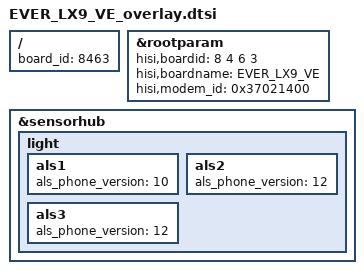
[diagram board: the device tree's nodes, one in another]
/**
 * Copyright (C) 2014 Hisilicon Ltd.
 *
 *  This program is free software; you can redistribute it and/or modify
 *  it under the terms of the GNU General Public License version 2 as
 *  publishhed by the Free Software Foundation.
 */


/include/ "EVER_LX9_VD_overlay.dtsi"

/ {
    board_id = <8463>;
};
	&rootparam{
		hisi,boardid = <8 4 6 3>;
		hisi,boardname = "EVER_LX9_VE";
		hisi,modem_id = <0x37021400>;
	};

	&sensorhub{
		light{
			als1{
				als_phone_version = <10>;
			};
			als2{
				als_phone_version = <12>;
			};
			als3{
				als_phone_version = <12>;
			};
		};
    };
